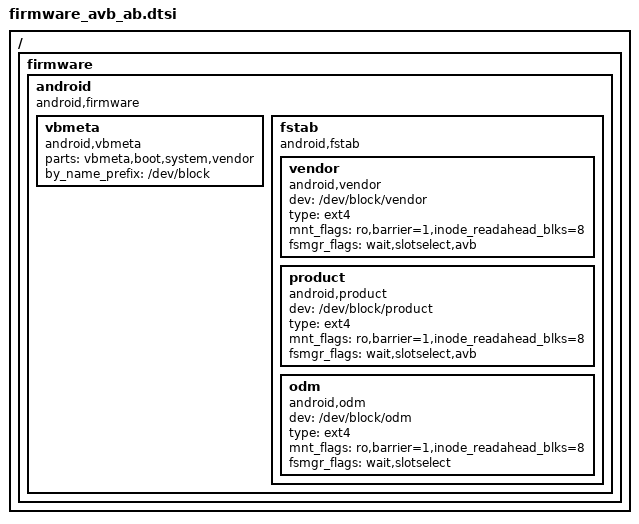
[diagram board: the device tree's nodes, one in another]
/*
 * arch/arm/boot/dts/amlogic/firmware_avb_ab.dtsi
 *
 * Copyright (C) 2017 Amlogic, Inc. All rights reserved.
 *
 * This program is free software; you can redistribute it and/or modify
 * it under the terms of the GNU General Public License as published by
 * the Free Software Foundation; either version 2 of the License, or
 * (at your option) any later version.
 *
 * This program is distributed in the hope that it will be useful, but WITHOUT
 * ANY WARRANTY; without even the implied warranty of MERCHANTABILITY or
 * FITNESS FOR A PARTICULAR PURPOSE.  See the GNU General Public License for
 * more details.
 *
 */

/ {
firmware {
	android {
		compatible = "android,firmware";
		vbmeta {
			compatible = "android,vbmeta";
			parts = "vbmeta,boot,system,vendor";
			by_name_prefix="/dev/block";
		};
	fstab {
		compatible = "android,fstab";

		vendor {
			compatible = "android,vendor";
			dev = "/dev/block/vendor";
			type = "ext4";
			mnt_flags = "ro,barrier=1,inode_readahead_blks=8";
			fsmgr_flags = "wait,slotselect,avb";
		};
		product {
			compatible = "android,product";
			dev = "/dev/block/product";
			type = "ext4";
			mnt_flags = "ro,barrier=1,inode_readahead_blks=8";
			fsmgr_flags = "wait,slotselect,avb";
		};
		odm {
			compatible = "android,odm";
			dev = "/dev/block/odm";
			type = "ext4";
			mnt_flags = "ro,barrier=1,inode_readahead_blks=8";
			fsmgr_flags = "wait,slotselect";
			};
		};
	};
};
};/* end of / */
